# MB9BF12xJ register map
File version: 1.2
CPU: 
Registers are 8-bit, read-write, reset 0x0 unless marked. A register's access mark holds for its fields unless they carry their own. Offsets are from the block's base; [hi:lo] are bit positions; {n}, {i} and the like mark numbered series.

## GPIO — General-purpose I/O ports
Base 0x40033000
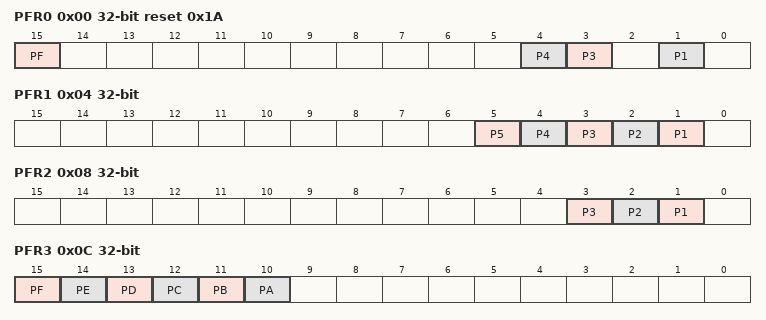
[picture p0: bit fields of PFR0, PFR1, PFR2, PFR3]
0x00 PFR0 32-bit reset 0x1A — Port function setting register 0
  [15] PF — Bit15 of PFR0
  [4] P4 — Bit4 of PFR0
  [3] P3 — Bit3 of PFR0
  [1] P1 — Bit1 of PFR0
0x04 PFR1 32-bit — Port function setting register 1
  [n] P{n} (n=1..5) — Bit{n} of PFR1
0x08 PFR2 32-bit — Port function setting register 2
  [3] P3 — Bit3 of PFR2
  [2] P2 — Bit2 of PFR2
  [1] P1 — Bit1 of PFR2
0x0C PFR3 32-bit — Port function setting register 3
  [15] PF — Bit15 of PFR3
  [14] PE — Bit14 of PFR3
  [13] PD — Bit13 of PFR3
  [12] PC — Bit12 of PFR3
  [11] PB — Bit11 of PFR3
  [10] PA — Bit10 of PFR3
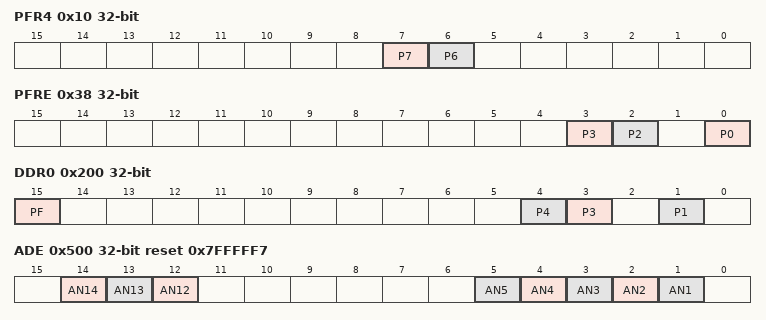
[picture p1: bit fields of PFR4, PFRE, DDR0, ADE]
0x10 PFR4 32-bit — Port function setting register 4
  [7] P7 — Bit7 of PFR4
  [6] P6 — Bit6 of PFR4
0x38 PFRE 32-bit — Port function setting register E
  [3] P3 — Bit3 of PFRE
  [2] P2 — Bit2 of PFRE
  [0] P0 — Bit0 of PFRE
{0x100+4i} PCR{i} 32-bit reset not defined (i=0..4) — Pull-up Setting Register {i}
0x138 PCRE 32-bit reset not defined — Pull-up Setting Register E
0x200 DDR0 32-bit — Port input/output direction setting register 0
  [15] PF — Bit15 of DDR0
  [4] P4 — Bit4 of DDR0
  [3] P3 — Bit3 of DDR0
  [1] P1 — Bit1 of DDR0
{0x200+4i} DDR{i} 32-bit reset not defined (i=1..4) — Port input/output direction setting register {i}
0x238 DDRE 32-bit reset not defined — Port input/output direction setting register E
{0x300+4i} PDIR{i} 32-bit reset not defined (i=0..4) — Port input data register {i}
0x338 PDIRE 32-bit reset not defined — Port input data register E
{0x400+4i} PDOR{i} 32-bit reset not defined (i=0..4) — Port output data register {i}
0x438 PDORE 32-bit reset not defined — Port output data register E
0x500 ADE 32-bit reset 0x7FFFFF7 (reset mask 0x7FFFFF7) — Analog input setting register
  [14] AN14 — Bit14 of ADE
  [13] AN13 — Bit13 of ADE
  [12] AN12 — Bit12 of ADE
  [n] AN{n} (n=1..5) — Bit{n} of ADE
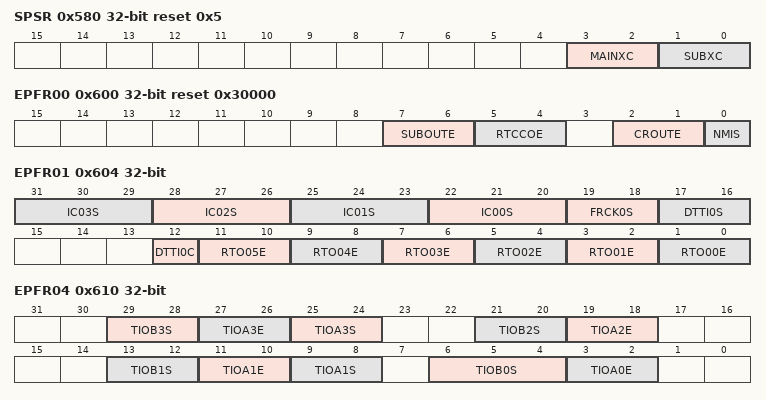
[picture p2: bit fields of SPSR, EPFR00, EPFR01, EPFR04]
0x580 SPSR 32-bit reset 0x5 — Special port setting register
  [3:2] MAINXC — Main clock(oscillation) pin setting bit
  [1:0] SUBXC — Sub clock(oscillation) pin setting bit
0x600 EPFR00 32-bit reset 0x30000 — Extended pin function setting register 00
  [7:6] SUBOUTE — Sub clock divide output function select bit
  [5:4] RTCCOE — RTC clock output select bit
  [2:1] CROUTE — Internal high-speed CR oscillation output function select bit
  [0] NMIS — NMIX function select bit
0x604 EPFR01 32-bit — Extended pin function setting register 01
  [3n+22:3n+20] IC{n:02}S (n=0..3) — IC{n:02} input select bit
  [19:18] FRCK0S — FRCK0 input select bit
  [17:16] DTTI0S — DTTIX0 input select bit
  [12] DTTI0C — DTTIX0 function select bit
  [2n+1:2n] RTO{n:02}E (n=0..5) — RTO{n:02}E output select bit
0x608 EPFR02 32-bit reset not defined — Extended pin function setting register 02
0x60C EPFR03 32-bit reset not defined — Extended pin function setting register 03
0x610 EPFR04 32-bit — Extended pin function setting register 04
  [29:28] TIOB3S — TIOB3 input select bit
  [27:26] TIOA3E — TIOA3E output select bit
  [25:24] TIOA3S — TIOA3 input select bit
  [21:20] TIOB2S — TIOB2 input select bit
  [19:18] TIOA2E — TIOA2 output select bit
  [13:12] TIOB1S — TIOB1 input select bit
  [11:10] TIOA1E — TIOA1E output select bit
  [9:8] TIOA1S — TIOA1 input select bit
  [6:4] TIOB0S — TIOB0 input select bit
  [3:2] TIOA0E — TIOA0 output select bit
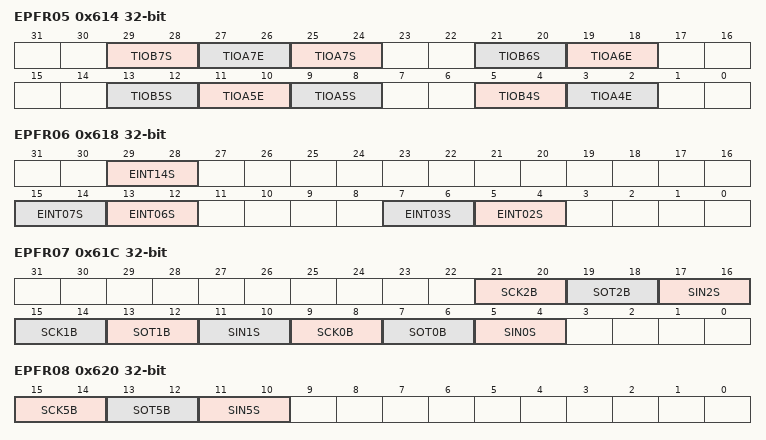
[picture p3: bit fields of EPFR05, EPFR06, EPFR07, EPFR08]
0x614 EPFR05 32-bit — Extended pin function setting register 05
  [29:28] TIOB7S — TIOB7 input select Bit
  [27:26] TIOA7E — TIOA7E output select bit
  [25:24] TIOA7S — TIOA7 input select bit
  [21:20] TIOB6S — TIOB6 input select bit
  [19:18] TIOA6E — TIOA6 output select bit
  [13:12] TIOB5S — TIOB5 input select bit
  [11:10] TIOA5E — TIOA5E output select bit
  [9:8] TIOA5S — TIOA5 input select bit
  [5:4] TIOB4S — TIOB4 input select bit
  [3:2] TIOA4E — TIOA4 output select bit
0x618 EPFR06 32-bit — Extended pin function setting register 06
  [29:28] EINT14S — External interrupt 14 input select bit
  [15:14] EINT07S — External interrupt 7 input select bit
  [13:12] EINT06S — External interrupt 6 input select bit
  [7:6] EINT03S — External interrupt 3 input select bit
  [5:4] EINT02S — External interrupt 2 input select bit
0x61C EPFR07 32-bit — Extended pin function setting register 07
  [21:20] SCK2B — SCK2 input/output select bit
  [19:18] SOT2B — SOT2B input/output select bit
  [17:16] SIN2S — SIN2S input select bit
  [15:14] SCK1B — SCK1 input/output select bit
  [13:12] SOT1B — SCK1B input/output select bit
  [11:10] SIN1S — SIN1S input select bit
  [9:8] SCK0B — SCK0 input/output select bit
  [7:6] SOT0B — SOT0B input/output select bit
  [5:4] SIN0S — SIN0S input select bit
0x620 EPFR08 32-bit — Extended pin function setting register 08
  [15:14] SCK5B — SCK5 input/output select bit
  [13:12] SOT5B — SOT5B input/output select bit
  [11:10] SIN5S — SIN5S input select bit
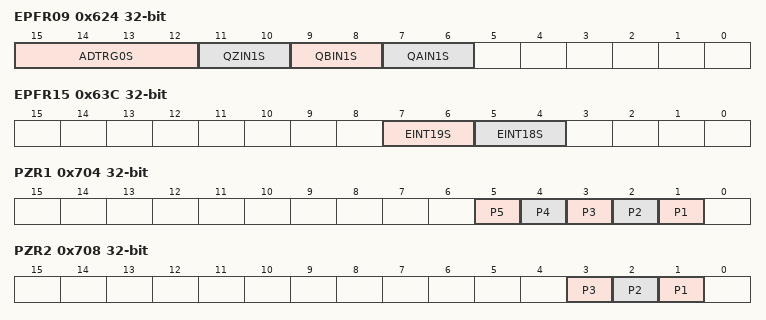
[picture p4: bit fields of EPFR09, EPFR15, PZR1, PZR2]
0x624 EPFR09 32-bit — Extended pin function setting register 09
  [15:12] ADTRG0S — ADTRG0 input select bit
  [11:10] QZIN1S — QZIN1S input select bit
  [9:8] QBIN1S — QBIN1S input select bit
  [7:6] QAIN1S — QAIN1S input select bit
{0x600+4i} EPFR{i} 32-bit reset not defined (i=10..14) — Extended pin function setting register {i}
0x63C EPFR15 32-bit — Extended pin function setting register 15
  [7:6] EINT19S — External interrupt 19 input select bit
  [5:4] EINT18S — External interrupt 18 input select bit
{0x600+4i} EPFR{i} 32-bit reset not defined (i=16..18) — Extended pin function setting register {i}
0x704 PZR1 32-bit — Port Pseudo Open Drain Setting Register 1
  [n] P{n} (n=1..5) — Bit{n} of PZR1
0x708 PZR2 32-bit — Port Pseudo Open Drain Setting Register 2
  [3] P3 — Bit3 of PZR2
  [2] P2 — Bit2 of PZR2
  [1] P1 — Bit1 of PZR2
